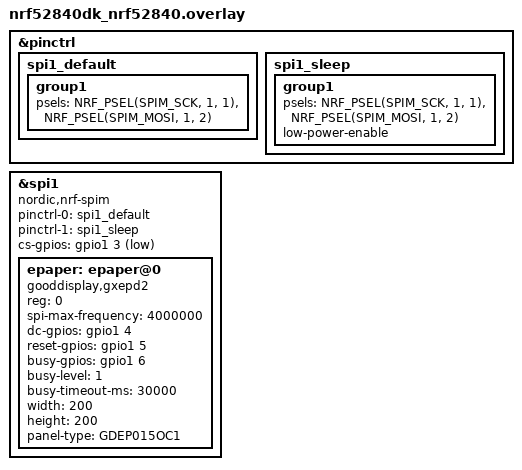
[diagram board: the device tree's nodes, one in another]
/*
 * Device Tree Overlay for nRF52840 DK
 * E-Paper Display Example Configuration
 *
 * This overlay configures SPI and GPIO pins for connecting an e-paper display
 * to the nRF52840 Development Kit.
 *
 * Default pin assignments (can be customized):
 * - SPI: spi1 (P1.01 = SCK, P1.02 = MOSI)
 * - CS:  P1.03
 * - DC:  P1.04
 * - RST: P1.05
 * - BUSY: P1.06
 */

&pinctrl {
    spi1_default: spi1_default {
        group1 {
            psels = <NRF_PSEL(SPIM_SCK, 1, 1)>,
                    <NRF_PSEL(SPIM_MOSI, 1, 2)>;
        };
    };

    spi1_sleep: spi1_sleep {
        group1 {
            psels = <NRF_PSEL(SPIM_SCK, 1, 1)>,
                    <NRF_PSEL(SPIM_MOSI, 1, 2)>;
            low-power-enable;
        };
    };
};

&spi1 {
    compatible = "nordic,nrf-spim";
    status = "okay";
    pinctrl-0 = <&spi1_default>;
    pinctrl-1 = <&spi1_sleep>;
    pinctrl-names = "default", "sleep";
    cs-gpios = <&gpio1 3 GPIO_ACTIVE_LOW>;

    epaper: epaper@0 {
        compatible = "gooddisplay,gxepd2";
        reg = <0>;
        spi-max-frequency = <4000000>;
        dc-gpios = <&gpio1 4 GPIO_ACTIVE_HIGH>;
        reset-gpios = <&gpio1 5 GPIO_ACTIVE_HIGH>;
        busy-gpios = <&gpio1 6 GPIO_ACTIVE_HIGH>;
        busy-level = <1>;
        busy-timeout-ms = <30000>;
        width = <200>;
        height = <200>;
        panel-type = "GDEP015OC1"; /* 1.54" 200x200 display - change as needed */
    };
};
